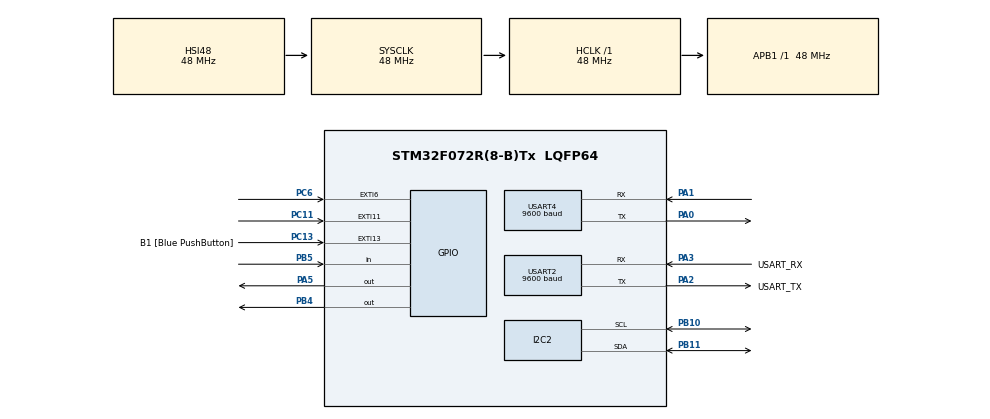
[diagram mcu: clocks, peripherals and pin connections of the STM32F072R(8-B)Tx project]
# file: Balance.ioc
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I2C2.Timing=0x20303E5D
Mcu.Family=STM32F0
Mcu.Name=STM32F072R(8-B)Tx
Mcu.Package=LQFP64
NVIC.EXTI4_15_IRQn=true\:0\:0\:false\:false\:true\:true\:true\:true
PA0.Mode=Asynchronous
PA0.Signal=USART4_TX
PA1.Mode=Asynchronous
PA1.Signal=USART4_RX
PA13.GPIO_Label=TMS
PA13.Mode=Serial_Wire
PA13.Signal=SYS_SWDIO
PA14.GPIO_Label=TCK
PA14.Mode=Serial_Wire
PA14.Signal=SYS_SWCLK
PA2.GPIO_Label=USART_TX
PA2.GPIO_Mode=GPIO_MODE_AF_PP
PA2.GPIO_PuPd=GPIO_NOPULL
PA2.GPIO_Speed=GPIO_SPEED_FREQ_LOW
PA2.Mode=Asynchronous
PA2.Signal=USART2_TX
PA3.GPIO_Label=USART_RX
PA3.GPIO_Mode=GPIO_MODE_AF_PP
PA3.GPIO_PuPd=GPIO_NOPULL
PA3.GPIO_Speed=GPIO_SPEED_FREQ_LOW
PA3.Mode=Asynchronous
PA3.Signal=USART2_RX
PA5.Signal=GPIO_Output
PB10.Mode=I2C
PB10.Signal=I2C2_SCL
PB11.Mode=I2C
PB11.Signal=I2C2_SDA
PB4.Signal=GPIO_Output
PB5.Signal=GPIO_Input
PC11.Signal=GPXTI11
PC13.GPIO_Label=B1 [Blue PushButton]
PC13.GPIO_ModeDefaultEXTI=GPIO_MODE_IT_FALLING
PC13.Signal=GPXTI13
PC14-OSC32_IN.Mode=LSE-External-Oscillator
PC14-OSC32_IN.Signal=RCC_OSC32_IN
PC15-OSC32_OUT.Mode=LSE-External-Oscillator
PC15-OSC32_OUT.Signal=RCC_OSC32_OUT
PC6.Signal=GPXTI6
PF0-OSC_IN.Mode=HSE-External-Clock-Source
PF0-OSC_IN.Signal=RCC_OSC_IN
PF1-OSC_OUT.Signal=RCC_OSC_OUT
ProjectManager.HeapSize=0x200
ProjectManager.StackSize=0x400
ProjectManager.TargetToolchain=STM32CubeIDE
RCC.AHBFreq_Value=48000000
RCC.APB1Freq_Value=48000000
RCC.APB1TimFreq_Value=48000000
RCC.FLatency-AdvancedSettings=FLASH_LATENCY_1
RCC.HCLKFreq_Value=48000000
RCC.PLLDivider=RCC_PREDIV_DIV2
RCC.PLLMUL=RCC_PLL_MUL12
RCC.PREFETCH_ENABLE-AdvancedSettings=1
RCC.SYSCLKFreq_VALUE=48000000
RCC.SYSCLKSource=RCC_SYSCLKSOURCE_HSI48
USART2.BaudRate=9600
USART2.VirtualMode-Asynchronous=VM_ASYNC
USART4.BaudRate=9600
USART4.VirtualMode-Asynchronous=VM_ASYNC
board=NUCLEO-F072RB

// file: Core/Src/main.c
/* USER CODE BEGIN Header */
/**
  ******************************************************************************
  * @file           : main.c
  * @brief          : Main program body
  ******************************************************************************
  * @attention
  *
  * Copyright (c) 2025 STMicroelectronics.
  * All rights reserved.
  *
  * This software is licensed under terms that can be found in the LICENSE file
  * in the root directory of this software component.
  * If no LICENSE file comes with this software, it is provided AS-IS.
  *
  ******************************************************************************
  */
/* USER CODE END Header */
#include "main.h"

I2C_HandleTypeDef hi2c2;

UART_HandleTypeDef huart2;
UART_HandleTypeDef huart4;

void SystemClock_Config(void);
static void MX_GPIO_Init(void);
static void MX_USART2_UART_Init(void);
static void MX_I2C2_Init(void);
static void MX_USART4_UART_Init(void);
/* USER CODE BEGIN PFP */
#define PUTCHAR_PROTOTYPE int __io_putchar(int ch)
/* USER CODE END PFP */

int main(void)
{

  /* MCU Configuration--------------------------------------------------------*/

  /* Reset of all peripherals, Initializes the Flash interface and the Systick. */
  HAL_Init();

  /* Configure the system clock */
  SystemClock_Config();

  /* Initialize all configured peripherals */
  MX_GPIO_Init();
  MX_USART2_UART_Init();
  MX_I2C2_Init();
  MX_USART4_UART_Init();
  /* USER CODE BEGIN 2 */
newmain();
  /* USER CODE END 2 */

  /* Infinite loop */
  while (1)
  {

  }
}

void SystemClock_Config(void)
{
  RCC_OscInitTypeDef RCC_OscInitStruct = {0};
  RCC_ClkInitTypeDef RCC_ClkInitStruct = {0};
  RCC_PeriphCLKInitTypeDef PeriphClkInit = {0};

  /** Initializes the RCC Oscillators according to the specified parameters
  * in the RCC_OscInitTypeDef structure.
  */
  RCC_OscInitStruct.OscillatorType = RCC_OSCILLATORTYPE_HSI48;
  RCC_OscInitStruct.HSI48State = RCC_HSI48_ON;
  RCC_OscInitStruct.PLL.PLLState = RCC_PLL_NONE;
  if (HAL_RCC_OscConfig(&RCC_OscInitStruct) != HAL_OK)
  {
    Error_Handler();
  }

  /** Initializes the CPU, AHB and APB buses clocks
  */
  RCC_ClkInitStruct.ClockType = RCC_CLOCKTYPE_HCLK|RCC_CLOCKTYPE_SYSCLK
                              |RCC_CLOCKTYPE_PCLK1;
  RCC_ClkInitStruct.SYSCLKSource = RCC_SYSCLKSOURCE_HSI48;
  RCC_ClkInitStruct.AHBCLKDivider = RCC_SYSCLK_DIV1;
  RCC_ClkInitStruct.APB1CLKDivider = RCC_HCLK_DIV1;

  if (HAL_RCC_ClockConfig(&RCC_ClkInitStruct, FLASH_LATENCY_1) != HAL_OK)
  {
    Error_Handler();
  }
  PeriphClkInit.PeriphClockSelection = RCC_PERIPHCLK_USART2;
  PeriphClkInit.Usart2ClockSelection = RCC_USART2CLKSOURCE_PCLK1;
  if (HAL_RCCEx_PeriphCLKConfig(&PeriphClkInit) != HAL_OK)
  {
    Error_Handler();
  }
}

static void MX_I2C2_Init(void)
{

  hi2c2.Instance = I2C2;
  hi2c2.Init.Timing = 0x20303E5D;
  hi2c2.Init.OwnAddress1 = 0;
  hi2c2.Init.AddressingMode = I2C_ADDRESSINGMODE_7BIT;
  hi2c2.Init.DualAddressMode = I2C_DUALADDRESS_DISABLE;
  hi2c2.Init.OwnAddress2 = 0;
  hi2c2.Init.OwnAddress2Masks = I2C_OA2_NOMASK;
  hi2c2.Init.GeneralCallMode = I2C_GENERALCALL_DISABLE;
  hi2c2.Init.NoStretchMode = I2C_NOSTRETCH_DISABLE;
  if (HAL_I2C_Init(&hi2c2) != HAL_OK)
  {
    Error_Handler();
  }

  /** Configure Analogue filter
  */
  if (HAL_I2CEx_ConfigAnalogFilter(&hi2c2, I2C_ANALOGFILTER_ENABLE) != HAL_OK)
  {
    Error_Handler();
  }

  /** Configure Digital filter
  */
  if (HAL_I2CEx_ConfigDigitalFilter(&hi2c2, 0) != HAL_OK)
  {
    Error_Handler();
  }

}

static void MX_USART2_UART_Init(void)
{

  huart2.Instance = USART2;
  huart2.Init.BaudRate = 9600;
  huart2.Init.WordLength = UART_WORDLENGTH_8B;
  huart2.Init.StopBits = UART_STOPBITS_1;
  huart2.Init.Parity = UART_PARITY_NONE;
  huart2.Init.Mode = UART_MODE_TX_RX;
  huart2.Init.HwFlowCtl = UART_HWCONTROL_NONE;
  huart2.Init.OverSampling = UART_OVERSAMPLING_16;
  huart2.Init.OneBitSampling = UART_ONE_BIT_SAMPLE_DISABLE;
  huart2.AdvancedInit.AdvFeatureInit = UART_ADVFEATURE_NO_INIT;
  if (HAL_UART_Init(&huart2) != HAL_OK)
  {
    Error_Handler();
  }

}

static void MX_USART4_UART_Init(void)
{

  huart4.Instance = USART4;
  huart4.Init.BaudRate = 9600;
  huart4.Init.WordLength = UART_WORDLENGTH_8B;
  huart4.Init.StopBits = UART_STOPBITS_1;
  huart4.Init.Parity = UART_PARITY_NONE;
  huart4.Init.Mode = UART_MODE_TX_RX;
  huart4.Init.HwFlowCtl = UART_HWCONTROL_NONE;
  huart4.Init.OverSampling = UART_OVERSAMPLING_16;
  huart4.Init.OneBitSampling = UART_ONE_BIT_SAMPLE_DISABLE;
  huart4.AdvancedInit.AdvFeatureInit = UART_ADVFEATURE_NO_INIT;
  if (HAL_UART_Init(&huart4) != HAL_OK)
  {
    Error_Handler();
  }

}

static void MX_GPIO_Init(void)
{
  GPIO_InitTypeDef GPIO_InitStruct = {0};

  /* GPIO Ports Clock Enable */
  __HAL_RCC_GPIOC_CLK_ENABLE();
  __HAL_RCC_GPIOF_CLK_ENABLE();
  __HAL_RCC_GPIOA_CLK_ENABLE();
  __HAL_RCC_GPIOB_CLK_ENABLE();

  /*Configure GPIO pin Output Level */
  HAL_GPIO_WritePin(GPIOA, GPIO_PIN_5, GPIO_PIN_RESET);

  /*Configure GPIO pin Output Level */
  HAL_GPIO_WritePin(GPIOB, GPIO_PIN_4, GPIO_PIN_RESET);

  /*Configure GPIO pin : B1_Pin */
  GPIO_InitStruct.Pin = B1_Pin;
  GPIO_InitStruct.Mode = GPIO_MODE_IT_FALLING;
  GPIO_InitStruct.Pull = GPIO_NOPULL;
  HAL_GPIO_Init(B1_GPIO_Port, &GPIO_InitStruct);

  /*Configure GPIO pin : PA5 */
  GPIO_InitStruct.Pin = GPIO_PIN_5;
  GPIO_InitStruct.Mode = GPIO_MODE_OUTPUT_PP;
  GPIO_InitStruct.Pull = GPIO_NOPULL;
  GPIO_InitStruct.Speed = GPIO_SPEED_FREQ_LOW;
  HAL_GPIO_Init(GPIOA, &GPIO_InitStruct);

  /*Configure GPIO pins : PC6 PC11 */
  GPIO_InitStruct.Pin = GPIO_PIN_6|GPIO_PIN_11;
  GPIO_InitStruct.Mode = GPIO_MODE_IT_RISING;
  GPIO_InitStruct.Pull = GPIO_NOPULL;
  HAL_GPIO_Init(GPIOC, &GPIO_InitStruct);

  /*Configure GPIO pin : PB4 */
  GPIO_InitStruct.Pin = GPIO_PIN_4;
  GPIO_InitStruct.Mode = GPIO_MODE_OUTPUT_PP;
  GPIO_InitStruct.Pull = GPIO_NOPULL;
  GPIO_InitStruct.Speed = GPIO_SPEED_FREQ_LOW;
  HAL_GPIO_Init(GPIOB, &GPIO_InitStruct);

  /*Configure GPIO pin : PB5 */
  GPIO_InitStruct.Pin = GPIO_PIN_5;
  GPIO_InitStruct.Mode = GPIO_MODE_INPUT;
  GPIO_InitStruct.Pull = GPIO_NOPULL;
  HAL_GPIO_Init(GPIOB, &GPIO_InitStruct);

  /* EXTI interrupt init*/
  HAL_NVIC_SetPriority(EXTI4_15_IRQn, 0, 0);
  HAL_NVIC_EnableIRQ(EXTI4_15_IRQn);

}

/* USER CODE BEGIN 4 */
/**
@brief Retargets the C library printf function to the USART.
None
@retval None
*/
PUTCHAR_PROTOTYPE
{
/* Place your implementation of fputc here */
/* e.g. write a character to the USART1 and Loop until the end of transmission */
HAL_UART_Transmit(&huart2, (uint8_t *)&ch, 1, 0xFFFF);

return ch;
}
/* USER CODE END 4 */

void Error_Handler(void)
{
  __disable_irq();
  while (1)
  {
  }
}
